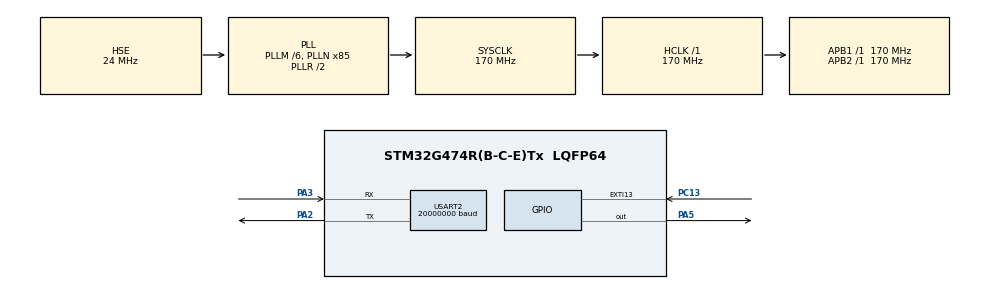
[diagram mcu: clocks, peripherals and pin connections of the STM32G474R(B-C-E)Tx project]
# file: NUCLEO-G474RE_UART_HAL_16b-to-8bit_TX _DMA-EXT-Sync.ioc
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Dma.Request0=USART2_TX
Dma.USART2_TX.0.Direction=DMA_MEMORY_TO_PERIPH
Dma.USART2_TX.0.EventEnable=DISABLE
Dma.USART2_TX.0.Instance=DMA1_Channel1
Dma.USART2_TX.0.MemDataAlignment=DMA_MDATAALIGN_BYTE
Dma.USART2_TX.0.MemInc=DMA_MINC_ENABLE
Dma.USART2_TX.0.Mode=DMA_CIRCULAR
Dma.USART2_TX.0.PeriphDataAlignment=DMA_PDATAALIGN_BYTE
Dma.USART2_TX.0.PeriphInc=DMA_PINC_DISABLE
Dma.USART2_TX.0.Polarity=HAL_DMAMUX_REQ_GEN_RISING
Dma.USART2_TX.0.Priority=DMA_PRIORITY_LOW
Dma.USART2_TX.0.RequestNumber=1
Dma.USART2_TX.0.SignalID=NONE
Dma.USART2_TX.0.SyncEnable=ENABLE
Dma.USART2_TX.0.SyncPolarity=HAL_DMAMUX_SYNC_RISING
Dma.USART2_TX.0.SyncRequestNumber=1
Dma.USART2_TX.0.SyncSignalID=HAL_DMAMUX1_SYNC_EXTI13
Mcu.Family=STM32G4
Mcu.Name=STM32G474R(B-C-E)Tx
Mcu.Package=LQFP64
NVIC.DMA1_Channel1_IRQn=true\:0\:0\:false\:false\:false\:false\:false
NVIC.DMAMUX_OVR_IRQn=true\:0\:0\:false\:false\:false\:false\:false
NVIC.PriorityGroup=NVIC_PRIORITYGROUP_4
PA13.Mode=Serial_Wire
PA13.Signal=SYS_JTMS-SWDIO
PA14.Mode=Serial_Wire
PA14.Signal=SYS_JTCK-SWCLK
PA2.GPIO_Speed=GPIO_SPEED_FREQ_HIGH
PA2.Mode=Asynchronous
PA2.Signal=USART2_TX
PA3.GPIO_Speed=GPIO_SPEED_FREQ_HIGH
PA3.Mode=Asynchronous
PA3.Signal=USART2_RX
PA5.Signal=GPIO_Output
PC13.Signal=GPXTI13
PC14-OSC32_IN.Mode=LSE-External-Oscillator
PC14-OSC32_IN.Signal=RCC_OSC32_IN
PC15-OSC32_OUT.Mode=LSE-External-Oscillator
PC15-OSC32_OUT.Signal=RCC_OSC32_OUT
PF0-OSC_IN.Mode=HSE-External-Oscillator
PF0-OSC_IN.Signal=RCC_OSC_IN
PF1-OSC_OUT.Mode=HSE-External-Oscillator
PF1-OSC_OUT.Signal=RCC_OSC_OUT
ProjectManager.HeapSize=0x200
ProjectManager.StackSize=0x400
ProjectManager.TargetToolchain=STM32CubeIDE
RCC.ADC12Freq_Value=170000000
RCC.ADC345Freq_Value=170000000
RCC.AHBFreq_Value=170000000
RCC.APB1Freq_Value=170000000
RCC.APB1TimFreq_Value=170000000
RCC.APB2Freq_Value=170000000
RCC.APB2TimFreq_Value=170000000
RCC.CortexFreq_Value=170000000
RCC.EXTERNAL_CLOCK_VALUE=12288000
RCC.HCLKFreq_Value=170000000
RCC.HSE_VALUE=24000000
RCC.HSI48_VALUE=48000000
RCC.HSI_VALUE=16000000
RCC.PLLM=RCC_PLLM_DIV6
RCC.PLLN=85
RCC.PLLSourceVirtual=RCC_PLLSOURCE_HSE
RCC.RTCClockSelection=RCC_RTCCLKSOURCE_LSE
RCC.SYSCLKFreq_VALUE=170000000
RCC.SYSCLKSource=RCC_SYSCLKSOURCE_PLLCLK
RCC.USBFreq_Value=170000000
RCC.VCOOutputFreq_Value=340000000
USART2.BaudRate=20000000
USART2.ClockPrescaler=PRESCALER_DIV1
USART2.MSBFirstParam=ADVFEATURE_MSBFIRST_DISABLE
USART2.OverSampling=UART_OVERSAMPLING_8
USART2.VirtualMode-Asynchronous=VM_ASYNC
VP_SYS_VS_DBSignals.Mode=DisableDeadBatterySignals
board=NUCLEO-G474RE

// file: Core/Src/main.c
/* USER CODE BEGIN Header */
/**
  ******************************************************************************
  * @file           : main.c
  * @brief          : Main program body
  ******************************************************************************
  * @attention
  *
  * <h2><center>&copy; Copyright (c) 2019 STMicroelectronics.
  * All rights reserved.</center></h2>
  *
  * This software component is licensed by ST under BSD 3-Clause license,
  * the "License"; You may not use this file except in compliance with the
  * License. You may obtain a copy of the License at:
  *                        opensource.org/licenses/BSD-3-Clause
  *
  ******************************************************************************
  */
/* USER CODE END Header */
#include "main.h"

/* USER CODE BEGIN Includes */

#include <string.h>
#include <sys/types.h>

/* USER CODE END Includes */

UART_HandleTypeDef huart2;
DMA_HandleTypeDef hdma_usart2_tx;

/* USER CODE BEGIN PV */

uint16_t msg[] = {0x0100, 0x0302, 0x0504, 0x0706};//"Test\r\n";
uint16_t lenght;

/* USER CODE END PV */

void SystemClock_Config(void);
static void MX_GPIO_Init(void);
static void MX_DMA_Init(void);
static void MX_USART2_UART_Init(void);

int main(void)
{

  /* MCU Configuration--------------------------------------------------------*/

  /* Reset of all peripherals, Initializes the Flash interface and the Systick. */
  HAL_Init();

  /* Configure the system clock */
  SystemClock_Config();

  /* Initialize all configured peripherals */
  MX_GPIO_Init();
  MX_DMA_Init();
  MX_USART2_UART_Init();
  /* USER CODE BEGIN 2 */

  lenght = sizeof(msg);

  /*##-1- Start the transmission process #####################################*/
  /* User start transmission data through "TxBuffer" buffer */
  if(HAL_UART_Transmit_DMA(&huart2, (uint8_t*)msg, lenght)!= HAL_OK)
  {
    /* Transfer error in transmission process */
    Error_Handler();
  }

  /* USER CODE END 2 */

  /* Infinite loop */
  while (1)
  {

  }
}

void SystemClock_Config(void)
{
  RCC_OscInitTypeDef RCC_OscInitStruct = {0};
  RCC_ClkInitTypeDef RCC_ClkInitStruct = {0};
  RCC_PeriphCLKInitTypeDef PeriphClkInit = {0};

  /** Configure the main internal regulator output voltage
  */
  HAL_PWREx_ControlVoltageScaling(PWR_REGULATOR_VOLTAGE_SCALE1_BOOST);
  /** Initializes the RCC Oscillators according to the specified parameters
  * in the RCC_OscInitTypeDef structure.
  */
  RCC_OscInitStruct.OscillatorType = RCC_OSCILLATORTYPE_HSE;
  RCC_OscInitStruct.HSEState = RCC_HSE_ON;
  RCC_OscInitStruct.PLL.PLLState = RCC_PLL_ON;
  RCC_OscInitStruct.PLL.PLLSource = RCC_PLLSOURCE_HSE;
  RCC_OscInitStruct.PLL.PLLM = RCC_PLLM_DIV6;
  RCC_OscInitStruct.PLL.PLLN = 85;
  RCC_OscInitStruct.PLL.PLLP = RCC_PLLP_DIV2;
  RCC_OscInitStruct.PLL.PLLQ = RCC_PLLQ_DIV2;
  RCC_OscInitStruct.PLL.PLLR = RCC_PLLR_DIV2;
  if (HAL_RCC_OscConfig(&RCC_OscInitStruct) != HAL_OK)
  {
    Error_Handler();
  }
  /** Initializes the CPU, AHB and APB buses clocks
  */
  RCC_ClkInitStruct.ClockType = RCC_CLOCKTYPE_HCLK|RCC_CLOCKTYPE_SYSCLK
                              |RCC_CLOCKTYPE_PCLK1|RCC_CLOCKTYPE_PCLK2;
  RCC_ClkInitStruct.SYSCLKSource = RCC_SYSCLKSOURCE_PLLCLK;
  RCC_ClkInitStruct.AHBCLKDivider = RCC_SYSCLK_DIV1;
  RCC_ClkInitStruct.APB1CLKDivider = RCC_HCLK_DIV1;
  RCC_ClkInitStruct.APB2CLKDivider = RCC_HCLK_DIV1;

  if (HAL_RCC_ClockConfig(&RCC_ClkInitStruct, FLASH_LATENCY_4) != HAL_OK)
  {
    Error_Handler();
  }
  /** Initializes the peripherals clocks
  */
  PeriphClkInit.PeriphClockSelection = RCC_PERIPHCLK_USART2;
  PeriphClkInit.Usart2ClockSelection = RCC_USART2CLKSOURCE_PCLK1;
  if (HAL_RCCEx_PeriphCLKConfig(&PeriphClkInit) != HAL_OK)
  {
    Error_Handler();
  }
}

static void MX_USART2_UART_Init(void)
{

  huart2.Instance = USART2;
  huart2.Init.BaudRate = 20000000;
  huart2.Init.WordLength = UART_WORDLENGTH_8B;
  huart2.Init.StopBits = UART_STOPBITS_1;
  huart2.Init.Parity = UART_PARITY_NONE;
  huart2.Init.Mode = UART_MODE_TX_RX;
  huart2.Init.HwFlowCtl = UART_HWCONTROL_NONE;
  huart2.Init.OverSampling = UART_OVERSAMPLING_8;
  huart2.Init.OneBitSampling = UART_ONE_BIT_SAMPLE_DISABLE;
  huart2.Init.ClockPrescaler = UART_PRESCALER_DIV1;
  huart2.AdvancedInit.AdvFeatureInit = UART_ADVFEATURE_NO_INIT;
  if (HAL_UART_Init(&huart2) != HAL_OK)
  {
    Error_Handler();
  }
  if (HAL_UARTEx_SetTxFifoThreshold(&huart2, UART_TXFIFO_THRESHOLD_1_8) != HAL_OK)
  {
    Error_Handler();
  }
  if (HAL_UARTEx_SetRxFifoThreshold(&huart2, UART_RXFIFO_THRESHOLD_1_8) != HAL_OK)
  {
    Error_Handler();
  }
  if (HAL_UARTEx_DisableFifoMode(&huart2) != HAL_OK)
  {
    Error_Handler();
  }

}

static void MX_DMA_Init(void)
{

  /* DMA controller clock enable */
  __HAL_RCC_DMAMUX1_CLK_ENABLE();
  __HAL_RCC_DMA1_CLK_ENABLE();

  /* DMA interrupt init */
  /* DMA1_Channel1_IRQn interrupt configuration */
  HAL_NVIC_SetPriority(DMA1_Channel1_IRQn, 0, 0);
  HAL_NVIC_EnableIRQ(DMA1_Channel1_IRQn);
  /* DMAMUX_OVR_IRQn interrupt configuration */
  HAL_NVIC_SetPriority(DMAMUX_OVR_IRQn, 0, 0);
  HAL_NVIC_EnableIRQ(DMAMUX_OVR_IRQn);

}

static void MX_GPIO_Init(void)
{
  GPIO_InitTypeDef GPIO_InitStruct = {0};

  /* GPIO Ports Clock Enable */
  __HAL_RCC_GPIOC_CLK_ENABLE();
  __HAL_RCC_GPIOF_CLK_ENABLE();
  __HAL_RCC_GPIOA_CLK_ENABLE();

  /*Configure GPIO pin Output Level */
  HAL_GPIO_WritePin(GPIOA, GPIO_PIN_5, GPIO_PIN_RESET);

  /*Configure GPIO pin : PC13 */
  GPIO_InitStruct.Pin = GPIO_PIN_13;
  GPIO_InitStruct.Mode = GPIO_MODE_IT_RISING;
  GPIO_InitStruct.Pull = GPIO_NOPULL;
  HAL_GPIO_Init(GPIOC, &GPIO_InitStruct);

  /*Configure GPIO pin : PA5 */
  GPIO_InitStruct.Pin = GPIO_PIN_5;
  GPIO_InitStruct.Mode = GPIO_MODE_OUTPUT_PP;
  GPIO_InitStruct.Pull = GPIO_NOPULL;
  GPIO_InitStruct.Speed = GPIO_SPEED_FREQ_LOW;
  HAL_GPIO_Init(GPIOA, &GPIO_InitStruct);

}

/* USER CODE BEGIN 4 */

size_t strlen(char const *s)
{
	size_t i;

	i= 0;
	while(s[i]) {
		i+= 1;
	}

	return i;
}

/* USER CODE END 4 */

void Error_Handler(void)
{
}

/************************ (C) COPYRIGHT STMicroelectronics *****END OF FILE****/
